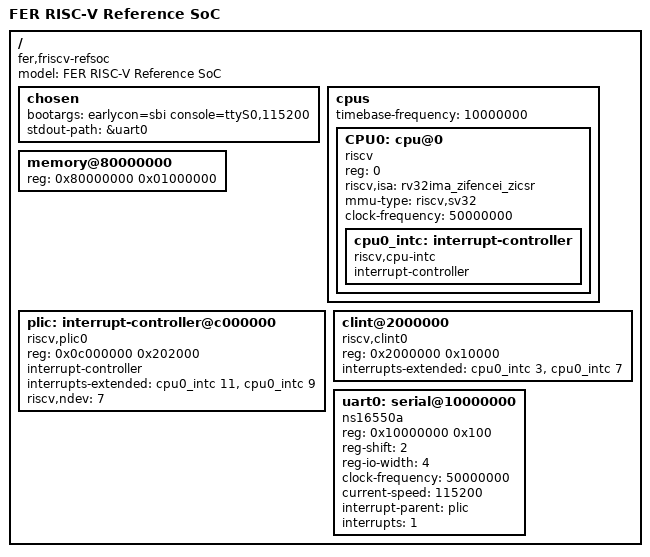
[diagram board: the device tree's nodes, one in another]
/ {
    #address-cells = <1>;
    #size-cells = <1>;
    model = "FER RISC-V Reference SoC";
    compatible = "fer,friscv-refsoc";

    chosen {
        bootargs = "earlycon=sbi console=ttyS0,115200";
        stdout-path = &uart0;
    };

    cpus {
        #address-cells = <1>;
        #size-cells = <0>;
        timebase-frequency = <10000000>;

        CPU0: cpu@0 {
            device_type = "cpu";
            compatible = "riscv";
            reg = <0>;
            status = "okay";
            riscv,isa = "rv32ima_zifencei_zicsr";
            mmu-type = "riscv,sv32";
            clock-frequency = <50000000>;

            cpu0_intc: interrupt-controller {
                #address-cells = <0>;
                #interrupt-cells = <1>;
                compatible = "riscv,cpu-intc";
                interrupt-controller;
            };
        };
    };

    memory@80000000 {
        device_type = "memory";
        reg = <0x80000000 0x01000000>;
    };

    plic: interrupt-controller@c000000 {
        compatible = "riscv,plic0";
        reg = <0x0c000000 0x202000>;
        interrupt-controller;
        #address-cells = <0>;
        #interrupt-cells = <1>;
        interrupts-extended = <&cpu0_intc 11>, <&cpu0_intc 9>;
        riscv,ndev = <7>;
    };

    clint@2000000 {
        compatible = "riscv,clint0";
        reg = <0x2000000 0x10000>;
        interrupts-extended = <&cpu0_intc 3>, <&cpu0_intc 7>;
    };

    uart0: serial@10000000 {
        compatible = "ns16550a";
        reg = <0x10000000 0x100>;
        reg-shift = <2>;
        reg-io-width = <4>;
        clock-frequency = <50000000>;
        current-speed = <115200>;
        interrupt-parent = <&plic>;
        interrupts = <1>;
    };
};
